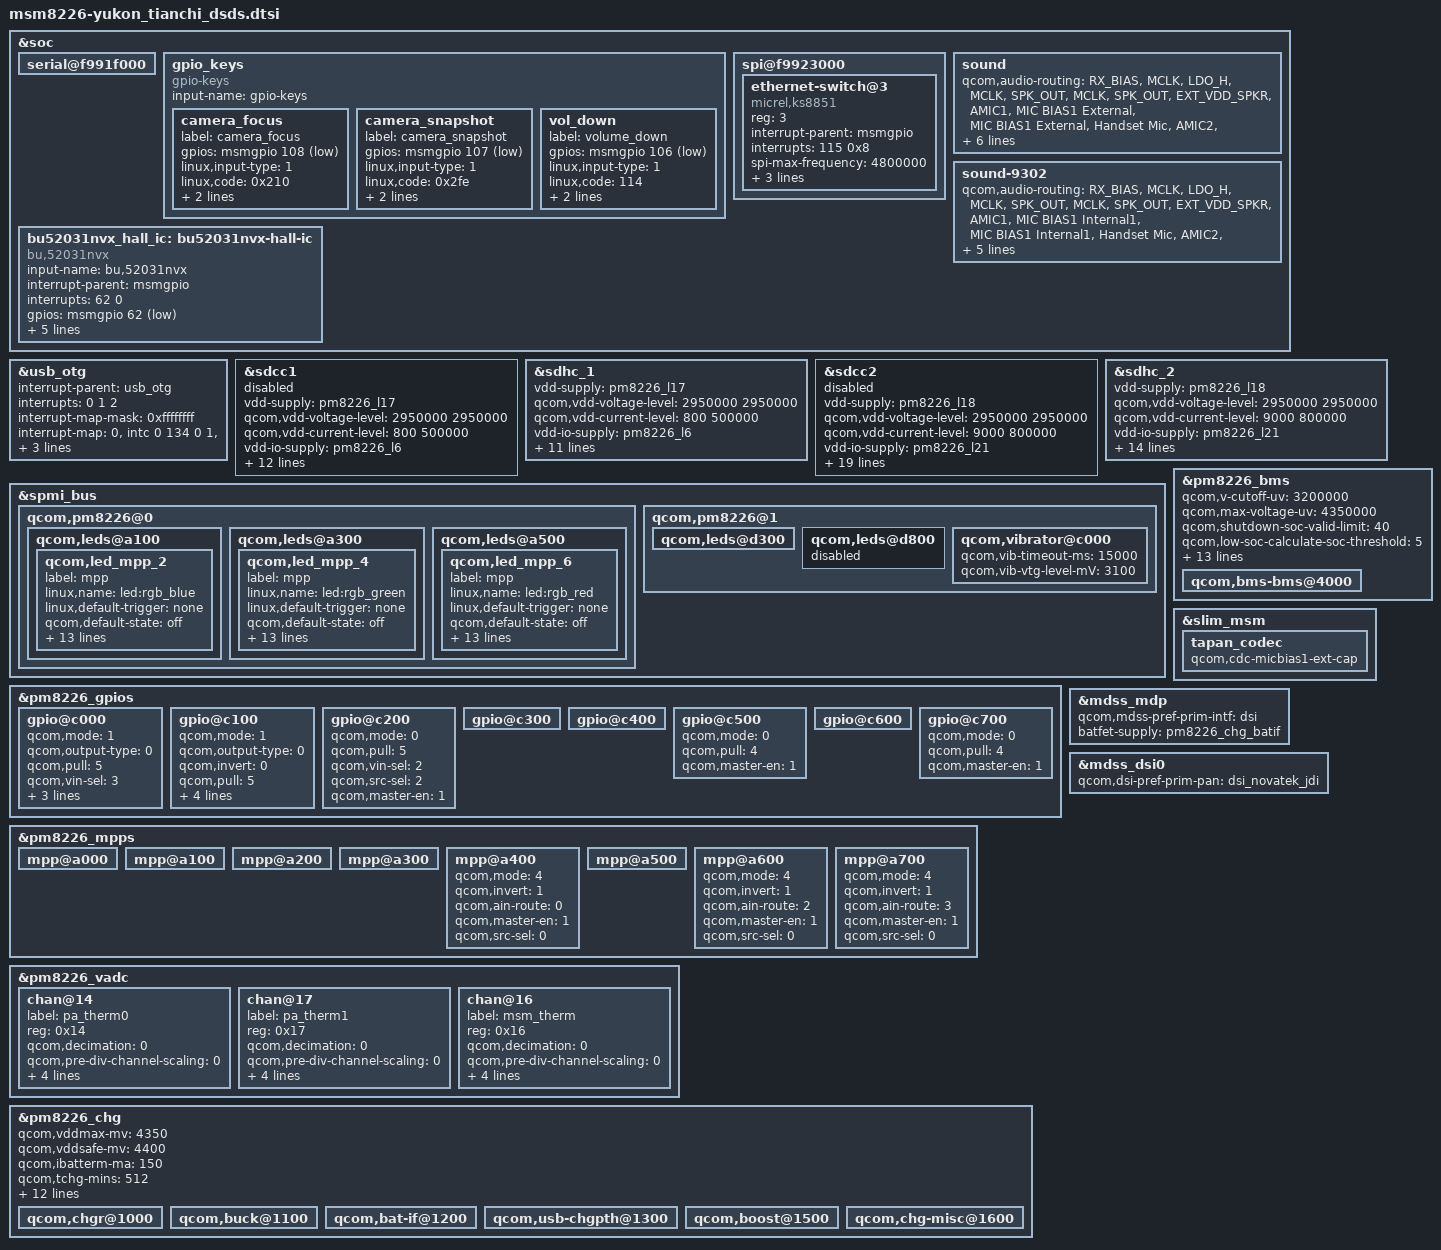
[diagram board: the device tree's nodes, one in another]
/* Copyright (c) 2013, The Linux Foundation. All rights reserved.
 * Copyright (C) 2014 Sony Mobile Communications AB.
 *
 * This program is free software; you can redistribute it and/or modify
 * it under the terms of the GNU General Public License version 2 and
 * only version 2 as published by the Free Software Foundation.
 *
 * This program is distributed in the hope that it will be useful,
 * but WITHOUT ANY WARRANTY; without even the implied warranty of
 * MERCHANTABILITY or FITNESS FOR A PARTICULAR PURPOSE.  See the
 * GNU General Public License for more details.
 *
 * NOTE: This file has been modified by Sony Mobile Communications AB.
 * Modifications are licensed under the License.
 */

&soc {
	serial@f991f000 {
		status = "ok";
	};

	gpio_keys {
		compatible = "gpio-keys";
		input-name = "gpio-keys";

		camera_focus {
			label = "camera_focus";
			gpios = <&msmgpio 108 0x1>;
			linux,input-type = <1>;
			linux,code = <0x210>;
			gpio-key,wakeup;
			debounce-interval = <15>;
		};

		camera_snapshot {
			label = "camera_snapshot";
			gpios = <&msmgpio 107 0x1>;
			linux,input-type = <1>;
			linux,code = <0x2fe>;
			gpio-key,wakeup;
			debounce-interval = <15>;
		};

		vol_down {
			label = "volume_down";
			gpios = <&msmgpio 106 0x1>;
			linux,input-type = <1>;
			linux,code = <114>;
			gpio-key,wakeup;
			debounce-interval = <15>;
		};
	};

	spi@f9923000 {
		ethernet-switch@3 {
			compatible = "micrel,ks8851";
			reg = <3>;
			interrupt-parent = <&msmgpio>;
			interrupts = <115 0x8>;
			spi-max-frequency = <4800000>;
			rst-gpio = <&msmgpio 114 0>;
			vdd-io-supply = <&pm8226_lvs1>;
			vdd-phy-supply = <&pm8226_lvs1>;
		};
	};

	sound {
		qcom,audio-routing =
			"RX_BIAS", "MCLK",
			"LDO_H", "MCLK",
			"SPK_OUT", "MCLK",
			"SPK_OUT", "EXT_VDD_SPKR",
			"AMIC1", "MIC BIAS1 External",
			"MIC BIAS1 External", "Handset Mic",
			"AMIC2", "MIC BIAS2 External",
			"MIC BIAS2 External", "Headset Mic",
			"AMIC3", "MIC BIAS1 External",
			"MIC BIAS1 External", "Secondary Mic";

		qcom,cdc-mclk-gpios = <&pm8226_gpios 1 0>;
		#qcom,cdc-vdd-spkr-gpios = <&pm8226_gpios 2 0>;
		qcom,headset-jack-type-NC;
	};

	sound-9302 {
		qcom,audio-routing =
			"RX_BIAS", "MCLK",
			"LDO_H", "MCLK",
			"SPK_OUT", "MCLK",
			"SPK_OUT", "EXT_VDD_SPKR",
			"AMIC1", "MIC BIAS1 Internal1",
			"MIC BIAS1 Internal1", "Handset Mic",
			"AMIC2", "MIC BIAS2 External",
			"MIC BIAS2 External", "Headset Mic",
			"AMIC3", "MIC BIAS1 External",
			"MIC BIAS1 External", "Handset Mic";

		qcom,cdc-mclk-gpios = <&pm8226_gpios 1 0>;
		qcom,cdc-vdd-spkr-gpios = <&pm8226_gpios 2 0>;
	};

	bu52031nvx_hall_ic: bu52031nvx-hall-ic {
		compatible = "bu,52031nvx";
		input-name = "bu,52031nvx";
		interrupt-parent = <&msmgpio>;
		interrupts = <62 0>;
		gpios = <&msmgpio 62 0x1>;
		linux,input-type = <0x05>;
		linux,code = <0x00>;
		gpio-key,wakeup;
		detection_delay = <50>;
		detection_cycles = <4>;
	};
};

&usb_otg {
	#address-cells = <0>;
	interrupt-parent = <&usb_otg>;
	interrupts = <0 1 2>;
	#interrupt-cells = <1>;
	interrupt-map-mask = <0xffffffff>;
	interrupt-map = <0 &intc 0 134 0
			1 &intc 0 140 0
			2 &spmi_bus 0x0 0x0 0x9 0x0>;
	interrupt-names = "core_irq", "async_irq", "pmic_id_irq";

	qcom,hsusb-otg-mode = <3>;
	vbus_otg-supply = <&pm8226_chg_otg>;
};

&sdcc1 {
	vdd-supply = <&pm8226_l17>;
	qcom,vdd-voltage-level = <2950000 2950000>;
	qcom,vdd-current-level = <800 500000>;

	vdd-io-supply = <&pm8226_l6>;
	qcom,vdd-io-always-on;
	qcom,vdd-io-voltage-level = <1800000 1800000>;
	qcom,vdd-io-current-level = <250 154000>;

	qcom,pad-pull-on = <0x0 0x3 0x3>; /* no-pull, pull-up, pull-up */
	qcom,pad-pull-off = <0x0 0x3 0x3>; /* no-pull, pull-up, pull-up */
	qcom,pad-drv-on = <0x4 0x4 0x4>; /* 10mA, 10mA, 10mA */
	qcom,pad-drv-off = <0x0 0x0 0x0>; /* 2mA, 2mA, 2mA */

	qcom,clk-rates = <400000 25000000 50000000 100000000 200000000>;
	qcom,sup-voltages = <2950 2950>;

	qcom,bus-speed-mode = "HS200_1p8v", "DDR_1p8v";
	qcom,nonremovable;

	status = "disabled";
};

&sdhc_1 {
	vdd-supply = <&pm8226_l17>;
	qcom,vdd-voltage-level = <2950000 2950000>;
	qcom,vdd-current-level = <800 500000>;

	vdd-io-supply = <&pm8226_l6>;
	qcom,vdd-io-always-on;
	qcom,vdd-io-voltage-level = <1800000 1800000>;
	qcom,vdd-io-current-level = <250 154000>;

	qcom,pad-pull-on = <0x0 0x3 0x3>; /* no-pull, pull-up, pull-up */
	qcom,pad-pull-off = <0x0 0x3 0x3>; /* no-pull, pull-up, pull-up */
	qcom,pad-drv-on = <0x4 0x4 0x4>; /* 10mA, 10mA, 10mA */
	qcom,pad-drv-off = <0x0 0x0 0x0>; /* 2mA, 2mA, 2mA */

	qcom,clk-rates = <400000 25000000 50000000 100000000 200000000>;
	qcom,bus-speed-mode = "DDR_1p8v";
	qcom,nonremovable;

	status = "ok";
};

&sdcc2 {
	vdd-supply = <&pm8226_l18>;
	qcom,vdd-voltage-level = <2950000 2950000>;
	qcom,vdd-current-level = <9000 800000>;

	vdd-io-supply = <&pm8226_l21>;
	qcom,vdd-io-voltage-level = <1800000 2950000>;
	qcom,vdd-io-current-level = <6 22000>;

	qcom,pad-pull-on = <0x0 0x3 0x3>; /* no-pull, pull-up, pull-up */
	qcom,pad-pull-off = <0x0 0x3 0x3>; /* no-pull, pull-up, pull-up */
	qcom,pad-drv-on = <0x4 0x4 0x4>; /* 10mA, 10mA, 10mA */
	qcom,pad-drv-off = <0x0 0x0 0x0>; /* 2mA, 2mA, 2mA */

	qcom,clk-rates = <400000 25000000 50000000 100000000 200000000>;
	qcom,sup-voltages = <2950 2950>;

	qcom,xpc;
	qcom,bus-speed-mode = "SDR12", "SDR25", "SDR50", "DDR50", "SDR104";
	qcom,current-limit = <600>; #address-cells = <0>; interrupt-parent = <&sdcc2>;
	interrupts = <0 1 2>;
	#interrupt-cells = <1>;
	interrupt-map-mask = <0xffffffff>;
	interrupt-map = <0 &intc 0 125 0
			1 &intc 0 220 0
			2 &msmgpio 38 0x3>;
	interrupt-names = "core_irq", "bam_irq", "status_irq";
	cd-gpios = <&msmgpio 38 0x1>;

	status = "disabled";
};

&sdhc_2 {
	vdd-supply = <&pm8226_l18>;
	qcom,vdd-voltage-level = <2950000 2950000>;
	qcom,vdd-current-level = <9000 800000>;

	vdd-io-supply = <&pm8226_l21>;
	qcom,vdd-io-voltage-level = <1800000 2950000>;
	qcom,vdd-io-current-level = <6 22000>;

	qcom,pad-pull-on = <0x0 0x3 0x3>; /* no-pull, pull-up, pull-up */
	qcom,pad-pull-off = <0x0 0x3 0x3>; /* no-pull, pull-up, pull-up */
	qcom,pad-drv-on = <0x3 0x3 0x3>; /* 8mA, 8mA, 8mA */
	qcom,pad-drv-off = <0x0 0x0 0x0>; /* 2mA, 2mA, 2mA */

	qcom,clk-rates = <400000 25000000 50000000 100000000 200000000>;

	#address-cells = <0>;
	interrupt-parent = <&sdhc_2>;
	interrupts = <0 1 2>;
	#interrupt-cells = <1>;
	interrupt-map-mask = <0xffffffff>;
	interrupt-map = <0 &intc 0 125 0
			1 &intc 0 221 0
			2 &msmgpio 38 0x3>;
	interrupt-names = "hc_irq", "pwr_irq", "status_irq";
	cd-gpios = <&msmgpio 38 0x1>;

	status = "ok";
};

&spmi_bus {
	qcom,pm8226@0 {
		qcom,leds@a100 {
			status = "okay";
			qcom,led_mpp_2 {
				label = "mpp";
				linux,name = "led:rgb_blue";
				linux,default-trigger = "none";
				qcom,default-state = "off";
				qcom,max-current = <40>;
				qcom,current-setting = <5>;
				qcom,id = <6>;
				qcom,mode = "pwm";
				qcom,pwm-us = <1000>;
				qcom,source-sel = <14>;
				qcom,mode-ctrl = <0x60>;
				qcom,pwm-channel = <3>;
				qcom,start-idx = <1>;
				qcom,ramp-step-ms = <120>;
				qcom,duty-pcts = [00 00 00 00 00
						  00 00 00 00 00
						  50 00 00 00 00
						  00 00 00 00 00
						  00];
				qcom,use-blink;
			};
		};

		qcom,leds@a300 {
			status = "okay";
			qcom,led_mpp_4 {
				label = "mpp";
				linux,name = "led:rgb_green";
				linux,default-trigger = "none";
				qcom,default-state = "off";
				qcom,max-current = <40>;
				qcom,current-setting = <5>;
				qcom,id = <6>;
				qcom,mode = "pwm";
				qcom,pwm-us = <1000>;
				qcom,source-sel = <8>;
				qcom,mode-ctrl = <0x60>;
				qcom,pwm-channel = <0>;
				qcom,start-idx = <1>;
				qcom,ramp-step-ms = <120>;
				qcom,duty-pcts = [00 00 00 00 00
						  00 00 00 00 00
						  50 00 00 00 00
						  00 00 00 00 00
						  00];
				qcom,use-blink;
			};
		};

		qcom,leds@a500 {
			status = "okay";
			qcom,led_mpp_6 {
				label = "mpp";
				linux,name = "led:rgb_red";
				linux,default-trigger = "none";
				qcom,default-state = "off";
				qcom,max-current = <40>;
				qcom,current-setting = <5>;
				qcom,id = <6>;
				qcom,mode = "pwm";
				qcom,pwm-us = <1000>;
				qcom,mode-ctrl = <0x60>;
				qcom,source-sel = <10>;
				qcom,pwm-channel = <5>;
				qcom,start-idx = <1>;
				qcom,ramp-step-ms = <120>;
				qcom,duty-pcts = [00 00 00 00 00
						  00 00 00 00 00
						  50 00 00 00 00
						  00 00 00 00 00
						  00];
				qcom,use-blink;
			};
		};
	};

	qcom,pm8226@1 {
                qcom,leds@d300 {
                        status = "okay";
                };

		qcom,leds@d800 {
			status = "disabled";
		};

		qcom,vibrator@c000 {
			status = "okay";
			qcom,vib-timeout-ms = <15000>;
			qcom,vib-vtg-level-mV = <3100>;
		};
	};
};

&pm8226_gpios {
	/* GPIO_1: PMIC_AUDIO_REF_CLLK*/
	/* Follow QCT */
	gpio@c000 {
		/* XO_PMIC_CDC_MCLK enable for tapan codec */
		qcom,mode = <1>;		/* Digital output */
		qcom,output-type = <0>;	/* CMOS logic */
		qcom,pull = <5>;		/* QPNP_PIN_PULL_NO*/
		qcom,vin-sel = <3>;		/* QPNP_PIN_VIN3 */
		qcom,out-strength = <3>;/* QPNP_PIN_OUT_STRENGTH_HIGH */
		qcom,src-sel = <2>;		/* QPNP_PIN_SEL_FUNC_1 */
		qcom,master-en = <1>;	/* Enable GPIO */
	};

	/* GPIO_2: NFC_EN*/
	gpio@c100 {
		qcom,mode = <1>; /* QPNP_PIN_MODE_DIG_OUT */
		qcom,output-type = <0>; /* QPNP_PIN_OUT_BUF_CMOS */
		qcom,invert = <0>; /* QPNP_PIN_INVERT_DISABLE */
		qcom,pull = <5>; /* QPNP_PIN_PULL_NO */
		qcom,vin-sel = <3>; /* QPNP_PIN_VIN3 = VREG_L6 */
		qcom,out-strength = <1>; /* QPNP_PIN_OUT_STRENGTH_LOW */
		qcom,src-sel = <0>; /* QPNP_PIN_SEL_FUNC_CONSTANT */
		qcom,master-en = <1>; /* enable this gpio */
	};

	/* GPIO_3: NFC_CLK_REQ*/
	gpio@c200 {
		qcom,mode = <0>;		/* QPNP_PIN_MODE_DIG_IN */
		qcom,pull = <5>;		/* QPNP_PIN_PULL_NO */
		qcom,vin-sel = <2>;		/* QPNP_PIN_VIN2 */
		qcom,src-sel = <2>;		/* QPNP_PIN_SEL_FUNC_1 */
		qcom,master-en = <1>;
	};

	/* GPIO_4: BATT_UIM_ALARM*/
	/* Follow QCT */
	gpio@c300 {
	};

	/* GPIO_5: FLASH_STROBE_TRIG*/
	/* Follow QCT */
	gpio@c400 {
	};

	/* GPIO_6: NC*/
	gpio@c500 {
		qcom,mode = <0>;		/* QPNP_PIN_MODE_DIG_IN */
		qcom,pull = <4>;		/* QPNP_PIN_PULL_DN */
		qcom,master-en = <1>;
	};

	/* GPIO_7: TX_GTR_THRESH*/
	/* Follow QCT */
	gpio@c600 {
	};

	/* GPIO_8: NC*/
	gpio@c700 {
		qcom,mode = <0>;		/* QPNP_PIN_MODE_DIG_IN */
		qcom,pull = <4>;		/* QPNP_PIN_PULL_DN */
		qcom,master-en = <1>;
	};
};

&pm8226_mpps {
	/* MPP_1: VREF_MSM_PX_MPP1 */
	/* Follow QCT */
	mpp@a000 {
	};

	/* MPP_2: LED3_SINK */
	mpp@a100 {
	};

	/* MPP_3: VREF_LDO_MPP3 */
	/* Follow QCT */
	mpp@a200 {
	};

	/* MPP_4: LED1_SINK */
	/* Follow QCT */
	mpp@a300 {
	};

	/* MPP_5: PA_THERMEL_0 */
	/* Follow QCT */
	mpp@a400 {
		/* PA_THERM0 config */
		qcom,mode = <4>; /* AIN input */
		qcom,invert = <1>; /* Enable MPP */
		qcom,ain-route = <0>; /* AMUX 5 */
		qcom,master-en = <1>;
		qcom,src-sel = <0>; /* Function constant */
	};

	/* MPP_6: LED2_SINK */
	/* Follow QCT */
	mpp@a500 {
	};

	/* MPP_7: MSM_THERMEL */
	mpp@a600 {
		/* MSM_THERM config */
		qcom,mode = <4>; /* AIN input */
		qcom,invert = <1>; /* Enable MPP */
		qcom,ain-route = <2>; /* AMUX 7 */
		qcom,master-en = <1>;
		qcom,src-sel = <0>; /* Function constant */
	};

	/* MPP_8: PA_THERMEL_1 */
	/* Follow QCT */
	mpp@a700 {
		/* PA_THERM1 config */
		qcom,mode = <4>; /* AIN input */
		qcom,invert = <1>; /* Enable MPP */
		qcom,ain-route = <3>; /* AMUX 8 */
		qcom,master-en = <1>;
		qcom,src-sel = <0>; /* Function constant */
	};
};

&pm8226_vadc {
	chan@14 {
		label = "pa_therm0";
		reg = <0x14>;
		qcom,decimation = <0>;
		qcom,pre-div-channel-scaling = <0>;
		qcom,calibration-type = "ratiometric";
		qcom,scale-function = <2>;
		qcom,hw-settle-time = <2>;
		qcom,fast-avg-setup = <0>;
	};

	chan@17 {
		label = "pa_therm1";
		reg = <0x17>;
		qcom,decimation = <0>;
		qcom,pre-div-channel-scaling = <0>;
		qcom,calibration-type = "ratiometric";
		qcom,scale-function = <2>;
		qcom,hw-settle-time = <2>;
		qcom,fast-avg-setup = <0>;
	};

	chan@16 {
		label = "msm_therm";
		reg = <0x16>;
		qcom,decimation = <0>;
		qcom,pre-div-channel-scaling = <0>;
		qcom,calibration-type = "ratiometric";
		qcom,scale-function = <2>;
		qcom,hw-settle-time = <2>;
		qcom,fast-avg-setup = <0>;
	};
};

&pm8226_bms {
	status = "ok";

	qcom,v-cutoff-uv = <3200000>;
	qcom,max-voltage-uv = <4350000>;
	qcom,shutdown-soc-valid-limit = <40>;
	qcom,low-soc-calculate-soc-threshold = <5>;
	qcom,low-soc-calculate-soc-ms = <1000>;
	qcom,calculate-soc-ms = <30000>;
	qcom,batt-type = <3>;
	qcom,use-external-rsense;
	qcom,ocv-voltage-high-threshold-uv = <3800000>;
	qcom,ocv-voltage-low-threshold-uv = <3750000>;
	qcom,clamp-soc-max-count = <2>;
	qcom,enable-fcc-learning;
	qcom,min-fcc-learning-soc = <20>;
	qcom,min-fcc-ocv-pc = <30>;
	qcom,min-fcc-learning-samples = <5>;
	qcom,fcc-resolution = <10>;
	qcom,chg-term-ua = <150000>;

	qcom,bms-bms@4000 {
		status = "ok";
	};
};

&pm8226_chg {
	status = "ok";

	qcom,vddmax-mv = <4350>;
	qcom,vddsafe-mv = <4400>;
	qcom,ibatterm-ma = <150>;
	qcom,tchg-mins = <512>;
	qcom,thermal-mitigation = <1500 1500 1100 900 700 500 300 200 100 0>;
	qcom,ibatmax-cool-ma = <900>;
	qcom,cool-bat-decidegc = <100>;
	qcom,cool-bat-mv = <4350>;
	qcom,ibatmax-warm-ma = <900>;
	qcom,warm-bat-decidegc = <450>;
	qcom,warm-bat-mv = <4200>;
	qcom,vbatdet-delta-mv = <20>;
	qcom,vbatdet-delta-soc = <1>;
	qcom,ibatmax-cool-ma = <900>;
	qcom,batt-hot-percentage = <25>;
	qcom,duty-cycle-100p;

	qcom,chgr@1000 {
		status = "ok";
	};

	qcom,buck@1100 {
		status = "ok";
	};

	qcom,bat-if@1200 {
		status = "ok";
	};

	qcom,usb-chgpth@1300 {
		status = "ok";
	};

	qcom,boost@1500 {
		status = "ok";
	};

	qcom,chg-misc@1600 {
		status = "ok";
	};
};

&slim_msm {
	tapan_codec {
		qcom,cdc-micbias1-ext-cap;
	};
};

&mdss_mdp {
	qcom,mdss-pref-prim-intf = "dsi";
	batfet-supply = <&pm8226_chg_batif>;
};

&mdss_dsi0 {
	qcom,dsi-pref-prim-pan = <&dsi_novatek_jdi>;
};

